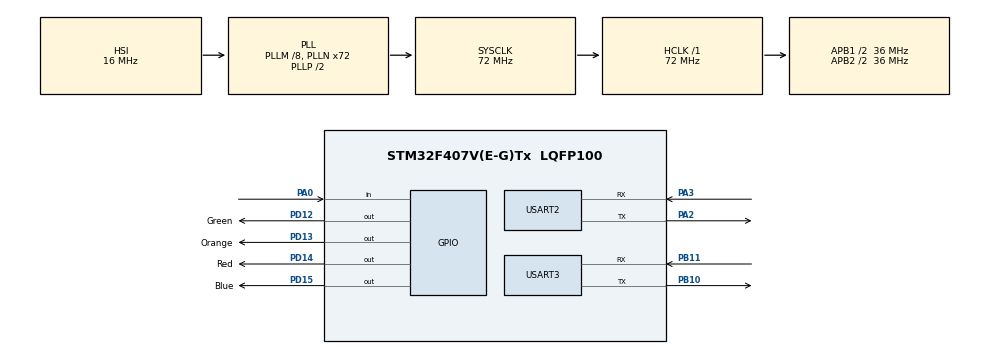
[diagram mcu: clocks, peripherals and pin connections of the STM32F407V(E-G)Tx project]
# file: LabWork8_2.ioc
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Mcu.Family=STM32F4
Mcu.Name=STM32F407V(E-G)Tx
Mcu.Package=LQFP100
NVIC.PriorityGroup=NVIC_PRIORITYGROUP_0
NVIC.TIM2_IRQn=true\:0\:0\:false\:true\:true\:1\:true\:true\:true
NVIC.TIM3_IRQn=true\:0\:0\:false\:true\:true\:2\:true\:true\:true
NVIC.USART2_IRQn=true\:0\:0\:false\:true\:true\:4\:true\:true\:true
NVIC.USART3_IRQn=true\:0\:0\:false\:true\:true\:3\:true\:true\:true
PA0-WKUP.Signal=GPIO_Input
PA2.Mode=Asynchronous
PA2.Signal=USART2_TX
PA3.Mode=Asynchronous
PA3.Signal=USART2_RX
PB10.Mode=Asynchronous
PB10.Signal=USART3_TX
PB11.Mode=Asynchronous
PB11.Signal=USART3_RX
PD12.GPIO_Label=Green
PD12.Signal=GPIO_Output
PD13.GPIO_Label=Orange
PD13.Signal=GPIO_Output
PD14.GPIO_Label=Red
PD14.Signal=GPIO_Output
PD15.GPIO_Label=Blue
PD15.Signal=GPIO_Output
ProjectManager.HeapSize=0x200
ProjectManager.StackSize=0x400
ProjectManager.TargetToolchain=STM32CubeIDE
RCC.48MHZClocksFreq_Value=20571428.57142857
RCC.AHBFreq_Value=72000000
RCC.APB1CLKDivider=RCC_HCLK_DIV2
RCC.APB1Freq_Value=36000000
RCC.APB1TimFreq_Value=72000000
RCC.APB2CLKDivider=RCC_HCLK_DIV2
RCC.APB2Freq_Value=36000000
RCC.APB2TimFreq_Value=72000000
RCC.CortexFreq_Value=72000000
RCC.HCLKFreq_Value=72000000
RCC.HSE_VALUE=8000000
RCC.HSI_VALUE=16000000
RCC.LSE_VALUE=32768
RCC.PLLM=8
RCC.PLLN=72
RCC.PLLQ=7
RCC.SYSCLKFreq_VALUE=72000000
RCC.SYSCLKSource=RCC_SYSCLKSOURCE_PLLCLK
RCC.VCOOutputFreq_Value=144000000
TIM2.Period=10800
TIM2.Prescaler=10000
TIM3.Period=28800-1
TIM3.Prescaler=10000-1
USART2.VirtualMode=VM_ASYNC
USART3.VirtualMode=VM_ASYNC
VP_TIM2_VS_ClockSourceINT.Mode=Internal
VP_TIM3_VS_ClockSourceINT.Mode=Internal
board=STM32F407G-DISC1

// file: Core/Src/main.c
/* USER CODE BEGIN Header */
/**
  ******************************************************************************
  * @file           : main.c
  * @brief          : Main program body
  ******************************************************************************
  * @attention
  *
  * Copyright (c) 2024 STMicroelectronics.
  * All rights reserved.
  *
  * This software is licensed under terms that can be found in the LICENSE file
  * in the root directory of this software component.
  * If no LICENSE file comes with this software, it is provided AS-IS.
  *
  ******************************************************************************
  */
/* USER CODE END Header */
#include "main.h"
#include "stm32f4xx_hal.h"

#define LONG_PRESS_COUNT 2  // 3 seconds or more (2*1.5s since ARR is set for 1.5s intervals)
#define LED_GREEN GPIO_PIN_12  // Represents bit 0
#define LED_ORANGE GPIO_PIN_13 // Represents bit 1
#define LED_RED    GPIO_PIN_14 // Represents bit 2

TIM_HandleTypeDef htim2;
TIM_HandleTypeDef htim3;

UART_HandleTypeDef huart2;
UART_HandleTypeDef huart3;

/* USER CODE BEGIN PV */
uint8_t currentNumber = 8;
const uint8_t winningNumber = 15; // Set by instructor
uint8_t gameWon = 0;
uint32_t buttonPressCounter = 0; // Assume globally defined
uint32_t longPressCount =2000;

/* USER CODE END PV */

void SystemClock_Config(void);
static void MX_GPIO_Init(void);
static void MX_TIM2_Init(void);
static void MX_TIM3_Init(void);
static void MX_USART2_UART_Init(void);
static void MX_USART3_UART_Init(void);
static void MX_NVIC_Init(void);
void HAL_TIM_PeriodElapsedCallback(TIM_HandleTypeDef *htim);
void displayNumber(uint8_t num);
void lightUpLEDs(uint8_t ledState);

int main(void)
{

  /* MCU Configuration--------------------------------------------------------*/

  /* Reset of all peripherals, Initializes the Flash interface and the Systick. */
  HAL_Init();

  /* Configure the system clock */
  SystemClock_Config();

  /* Initialize all configured peripherals */
  MX_GPIO_Init();
  MX_TIM2_Init();
  MX_TIM3_Init();
  MX_USART2_UART_Init();
  MX_USART3_UART_Init();

  /* Initialize interrupts */
  MX_NVIC_Init();
  /* USER CODE BEGIN 2 */
  HAL_TIM_Base_Start_IT(&htim3); // Start TIM3 in interrupt mode to cycle numbers

  uint8_t txBuffer[8]= {8,9,10,11,12,13,14,15};
  uint8_t rxBuffer=0; // Buffer for received data
  int send =0;

  /* USER CODE END 2 */

  /* Infinite loop */
  /* USER CODE BEGIN WHILE */
  while (1)
     {

	    if(send >7)
	    {
	    	send=0;
	    }

		  HAL_UART_Transmit(&huart2, &txBuffer[send], 1, HAL_MAX_DELAY);
		  HAL_UART_Receive(&huart3, &rxBuffer, 1, 1000);
		  send++;
		  rxBuffer=currentNumber;

       if (HAL_GPIO_ReadPin(GPIOA, GPIO_PIN_0) == GPIO_PIN_SET) // Button is pressed
       {
           if (buttonPressCounter == 0) // Start TIM2 if not already started
           {
               HAL_TIM_Base_Start_IT(&htim2);
           }
       }
       else // Button is released
       {
           HAL_TIM_Base_Stop_IT(&htim2); // Stop TIM2

           if (buttonPressCounter > 0) // Button was previously pressed
           {
               if (buttonPressCounter < LONG_PRESS_COUNT) // Short Press
               {
                   if (!gameWon && currentNumber == winningNumber) {
                       gameWon = 1;
                   }
               }
               else // Long Press
               {
                   if (gameWon) {
                       gameWon = 0;
                       currentNumber = 8;
                   }
               }
               buttonPressCounter = 0; // Reset the counter for the next press
           }
       }

       if (gameWon) {
           lightUpLEDs(0x07); // Turn on all LEDs to indicate a win
       }
     }
}

  void HAL_TIM_PeriodElapsedCallback(TIM_HandleTypeDef *htim)
  {
      if (htim->Instance == TIM2)
      {
          buttonPressCounter++; // Increment the counter on each TIM2 overflow
      }
      else if (htim->Instance == TIM3 && !gameWon)
      {
          currentNumber++;
          if (currentNumber > 15) {
              currentNumber = 8;
          }
          displayNumber(currentNumber); // Update LEDs with the current number
      }
  }

  void displayNumber(uint8_t num) {
      uint8_t convertedNum = num - 8;
      lightUpLEDs(convertedNum);
  }

  void lightUpLEDs(uint8_t ledState) {
      HAL_GPIO_WritePin(GPIOD, LED_GREEN | LED_ORANGE | LED_RED, GPIO_PIN_RESET);
      if(ledState & 0x01) HAL_GPIO_WritePin(GPIOD, LED_GREEN, GPIO_PIN_SET);
      if(ledState & 0x02) HAL_GPIO_WritePin(GPIOD, LED_ORANGE, GPIO_PIN_SET);
      if(ledState & 0x04) HAL_GPIO_WritePin(GPIOD, LED_RED, GPIO_PIN_SET);
  }

void SystemClock_Config(void)
{
  RCC_OscInitTypeDef RCC_OscInitStruct = {0};
  RCC_ClkInitTypeDef RCC_ClkInitStruct = {0};

  /** Configure the main internal regulator output voltage
  */
  __HAL_RCC_PWR_CLK_ENABLE();
  __HAL_PWR_VOLTAGESCALING_CONFIG(PWR_REGULATOR_VOLTAGE_SCALE1);

  /** Initializes the RCC Oscillators according to the specified parameters
  * in the RCC_OscInitTypeDef structure.
  */
  RCC_OscInitStruct.OscillatorType = RCC_OSCILLATORTYPE_HSI;
  RCC_OscInitStruct.HSIState = RCC_HSI_ON;
  RCC_OscInitStruct.HSICalibrationValue = RCC_HSICALIBRATION_DEFAULT;
  RCC_OscInitStruct.PLL.PLLState = RCC_PLL_ON;
  RCC_OscInitStruct.PLL.PLLSource = RCC_PLLSOURCE_HSI;
  RCC_OscInitStruct.PLL.PLLM = 8;
  RCC_OscInitStruct.PLL.PLLN = 72;
  RCC_OscInitStruct.PLL.PLLP = RCC_PLLP_DIV2;
  RCC_OscInitStruct.PLL.PLLQ = 7;
  if (HAL_RCC_OscConfig(&RCC_OscInitStruct) != HAL_OK)
  {
    Error_Handler();
  }

  /** Initializes the CPU, AHB and APB buses clocks
  */
  RCC_ClkInitStruct.ClockType = RCC_CLOCKTYPE_HCLK|RCC_CLOCKTYPE_SYSCLK
                              |RCC_CLOCKTYPE_PCLK1|RCC_CLOCKTYPE_PCLK2;
  RCC_ClkInitStruct.SYSCLKSource = RCC_SYSCLKSOURCE_PLLCLK;
  RCC_ClkInitStruct.AHBCLKDivider = RCC_SYSCLK_DIV1;
  RCC_ClkInitStruct.APB1CLKDivider = RCC_HCLK_DIV2;
  RCC_ClkInitStruct.APB2CLKDivider = RCC_HCLK_DIV2;

  if (HAL_RCC_ClockConfig(&RCC_ClkInitStruct, FLASH_LATENCY_2) != HAL_OK)
  {
    Error_Handler();
  }
}

/**
  * @brief NVIC Configuration.
  * @retval None
  */
static void MX_NVIC_Init(void)
{
  /* TIM2_IRQn interrupt configuration */
  HAL_NVIC_SetPriority(TIM2_IRQn, 0, 0);
  HAL_NVIC_EnableIRQ(TIM2_IRQn);
  /* TIM3_IRQn interrupt configuration */
  HAL_NVIC_SetPriority(TIM3_IRQn, 0, 0);
  HAL_NVIC_EnableIRQ(TIM3_IRQn);
  /* USART3_IRQn interrupt configuration */
  HAL_NVIC_SetPriority(USART3_IRQn, 0, 0);
  HAL_NVIC_EnableIRQ(USART3_IRQn);
  /* USART2_IRQn interrupt configuration */
  HAL_NVIC_SetPriority(USART2_IRQn, 0, 0);
  HAL_NVIC_EnableIRQ(USART2_IRQn);
}

static void MX_TIM2_Init(void)
{

  TIM_ClockConfigTypeDef sClockSourceConfig = {0};
  TIM_MasterConfigTypeDef sMasterConfig = {0};

  htim2.Instance = TIM2;
  htim2.Init.Prescaler = 10000-1;
  htim2.Init.CounterMode = TIM_COUNTERMODE_UP;
  htim2.Init.Period = 10800-1;
  htim2.Init.ClockDivision = TIM_CLOCKDIVISION_DIV1;
  htim2.Init.AutoReloadPreload = TIM_AUTORELOAD_PRELOAD_DISABLE;
  if (HAL_TIM_Base_Init(&htim2) != HAL_OK)
  {
    Error_Handler();
  }
  sClockSourceConfig.ClockSource = TIM_CLOCKSOURCE_INTERNAL;
  if (HAL_TIM_ConfigClockSource(&htim2, &sClockSourceConfig) != HAL_OK)
  {
    Error_Handler();
  }
  sMasterConfig.MasterOutputTrigger = TIM_TRGO_RESET;
  sMasterConfig.MasterSlaveMode = TIM_MASTERSLAVEMODE_DISABLE;
  if (HAL_TIMEx_MasterConfigSynchronization(&htim2, &sMasterConfig) != HAL_OK)
  {
    Error_Handler();
  }

}

static void MX_TIM3_Init(void)
{

  TIM_ClockConfigTypeDef sClockSourceConfig = {0};
  TIM_MasterConfigTypeDef sMasterConfig = {0};

  htim3.Instance = TIM3;
  htim3.Init.Prescaler = 10000-1;
  htim3.Init.CounterMode = TIM_COUNTERMODE_UP;
  htim3.Init.Period = 28800-1;
  htim3.Init.ClockDivision = TIM_CLOCKDIVISION_DIV1;
  htim3.Init.AutoReloadPreload = TIM_AUTORELOAD_PRELOAD_DISABLE;
  if (HAL_TIM_Base_Init(&htim3) != HAL_OK)
  {
    Error_Handler();
  }
  sClockSourceConfig.ClockSource = TIM_CLOCKSOURCE_INTERNAL;
  if (HAL_TIM_ConfigClockSource(&htim3, &sClockSourceConfig) != HAL_OK)
  {
    Error_Handler();
  }
  sMasterConfig.MasterOutputTrigger = TIM_TRGO_RESET;
  sMasterConfig.MasterSlaveMode = TIM_MASTERSLAVEMODE_DISABLE;
  if (HAL_TIMEx_MasterConfigSynchronization(&htim3, &sMasterConfig) != HAL_OK)
  {
    Error_Handler();
  }

}

static void MX_USART2_UART_Init(void)
{

  huart2.Instance = USART2;
  huart2.Init.BaudRate = 115200;
  huart2.Init.WordLength = UART_WORDLENGTH_8B;
  huart2.Init.StopBits = UART_STOPBITS_1;
  huart2.Init.Parity = UART_PARITY_NONE;
  huart2.Init.Mode = UART_MODE_TX_RX;
  huart2.Init.HwFlowCtl = UART_HWCONTROL_NONE;
  huart2.Init.OverSampling = UART_OVERSAMPLING_16;
  if (HAL_UART_Init(&huart2) != HAL_OK)
  {
    Error_Handler();
  }

}

static void MX_USART3_UART_Init(void)
{

  huart3.Instance = USART3;
  huart3.Init.BaudRate = 115200;
  huart3.Init.WordLength = UART_WORDLENGTH_8B;
  huart3.Init.StopBits = UART_STOPBITS_1;
  huart3.Init.Parity = UART_PARITY_NONE;
  huart3.Init.Mode = UART_MODE_TX_RX;
  huart3.Init.HwFlowCtl = UART_HWCONTROL_NONE;
  huart3.Init.OverSampling = UART_OVERSAMPLING_16;
  if (HAL_UART_Init(&huart3) != HAL_OK)
  {
    Error_Handler();
  }

}

static void MX_GPIO_Init(void)
{
  GPIO_InitTypeDef GPIO_InitStruct = {0};

  /* GPIO Ports Clock Enable */
  __HAL_RCC_GPIOA_CLK_ENABLE();
  __HAL_RCC_GPIOB_CLK_ENABLE();
  __HAL_RCC_GPIOD_CLK_ENABLE();

  /*Configure GPIO pin Output Level */
  HAL_GPIO_WritePin(GPIOD, Green_Pin|Orange_Pin|Red_Pin|Blue_Pin, GPIO_PIN_RESET);

  /*Configure GPIO pin : PA0 */
  GPIO_InitStruct.Pin = GPIO_PIN_0;
  GPIO_InitStruct.Mode = GPIO_MODE_INPUT;
  GPIO_InitStruct.Pull = GPIO_NOPULL;
  HAL_GPIO_Init(GPIOA, &GPIO_InitStruct);

  /*Configure GPIO pins : Green_Pin Orange_Pin Red_Pin Blue_Pin */
  GPIO_InitStruct.Pin = Green_Pin|Orange_Pin|Red_Pin|Blue_Pin;
  GPIO_InitStruct.Mode = GPIO_MODE_OUTPUT_PP;
  GPIO_InitStruct.Pull = GPIO_NOPULL;
  GPIO_InitStruct.Speed = GPIO_SPEED_FREQ_LOW;
  HAL_GPIO_Init(GPIOD, &GPIO_InitStruct);

}

void Error_Handler(void)
{
  __disable_irq();
  while (1)
  {
  }
}
